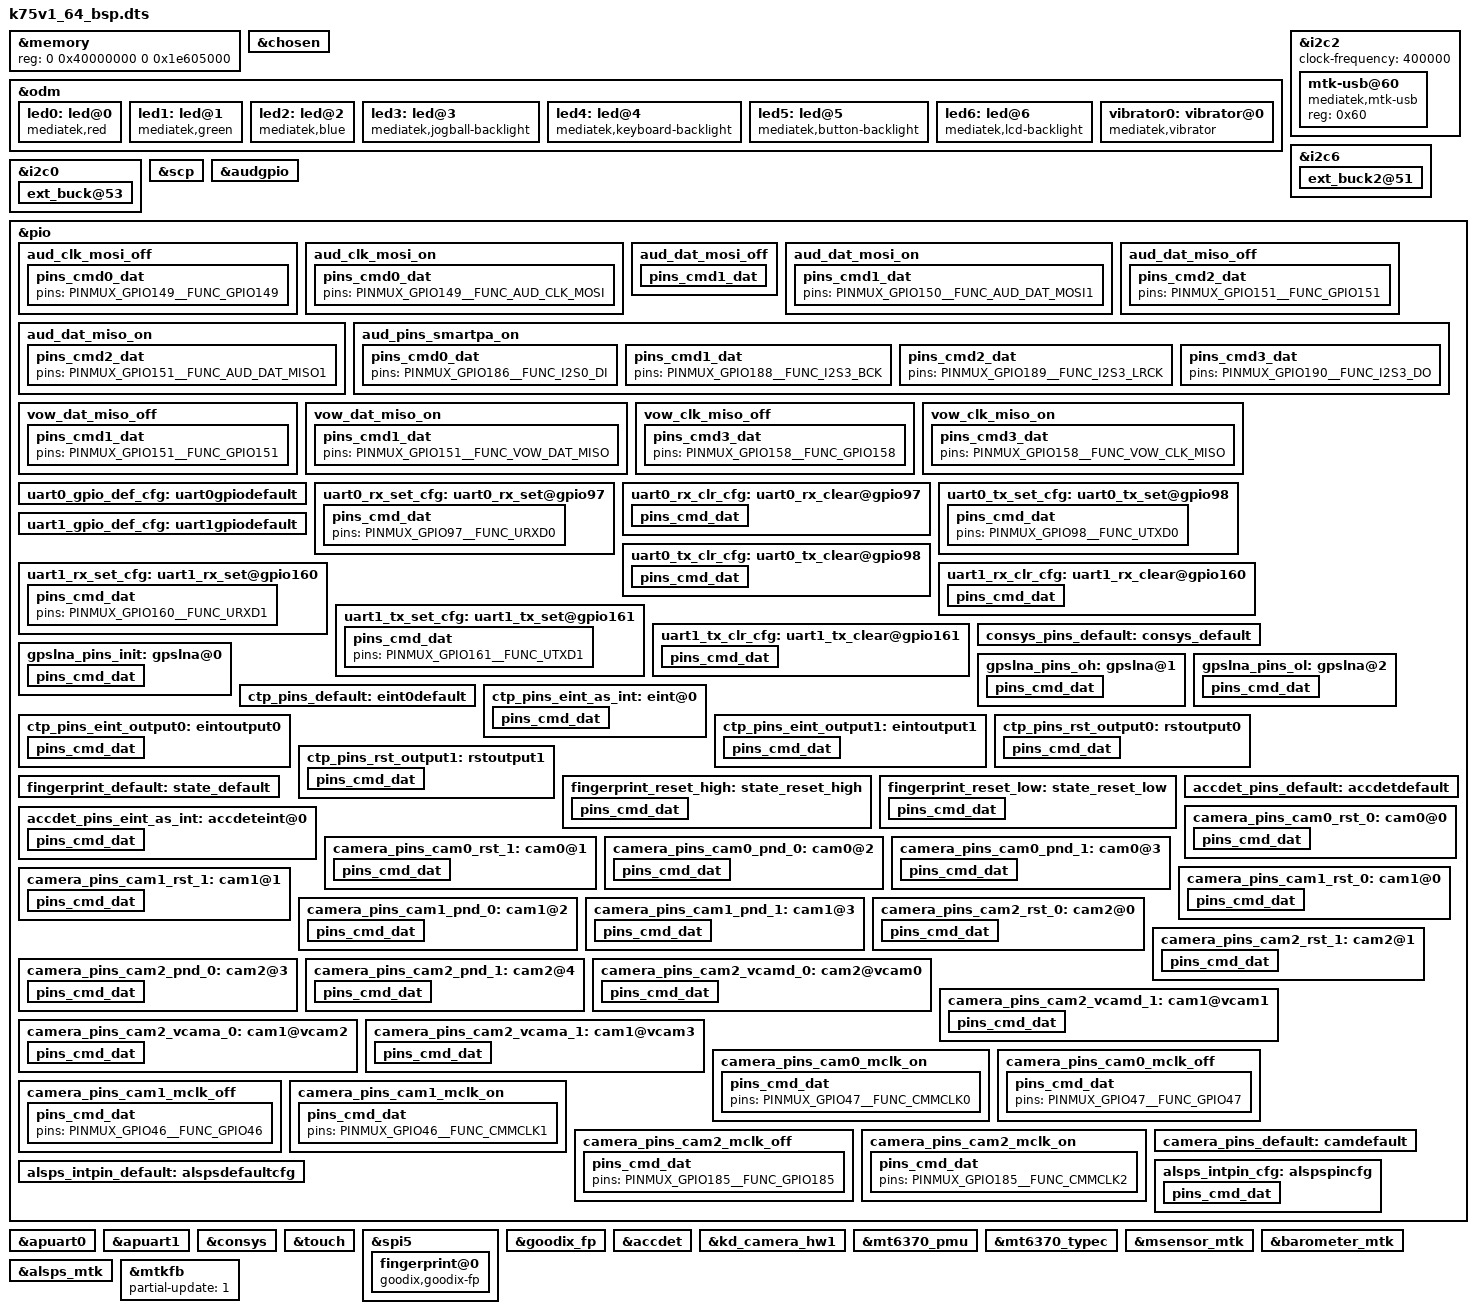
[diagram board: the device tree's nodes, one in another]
/dts-v1/;
/plugin/;
#include <dt-bindings/interrupt-controller/arm-gic.h>
#include <dt-bindings/interrupt-controller/irq.h>
#include <dt-bindings/pinctrl/mt6775-pinfunc.h>

&memory {
	device_type = "memory";
	reg = <0 0x40000000 0 0x1e605000>;
};

/* chosen */
&chosen {
	bootargs = "console=tty0 console=ttyMT0,921600n1 root=/dev/ram \
initrd=0x45000000,0x3000000 loglevel=8 \
androidboot.selinux=permissive androidboot.hardware=mt6775 \
initcall_debug=1";
	/* fpga may has no lk, we need to specify display info here */
	/* fb buffer is reserved using this dts by memory node above */

	atag,videolfb-fb_base_l = <0x5e605000>;
	atag,videolfb-fb_base_h = <0x0>;
	atag,videolfb-islcmfound = <1>;
	atag,videolfb-islcm_inited = <0>;
	atag,videolfb-fps= <6000>;
	atag,videolfb-vramSize= <0x017bb000>;
	/* atag,videolfb-lcmname= "nt35695B_fhd_dsi_cmd_truly_rt5081_lcm_drv"; */
	atag,videolfb-lcmname= "nt35695B_fhd_dsi_cmd_auo_rt5081_drv";

};

&odm {
	led0:led@0 {
		compatible = "mediatek,red";
		led_mode = <0>;
		data = <1>;
		pwm_config = <0 0 0 0 0>;
	};
	led1:led@1 {
		compatible = "mediatek,green";
		led_mode = <0>;
		data = <1>;
		pwm_config = <0 0 0 0 0>;
	};
	led2:led@2 {
		compatible = "mediatek,blue";
		led_mode = <0>;
		data = <1>;
		pwm_config = <0 0 0 0 0>;
	};
	led3:led@3 {
		compatible = "mediatek,jogball-backlight";
		led_mode = <0>;
		data = <1>;
		pwm_config = <0 0 0 0 0>;
	};
	led4:led@4 {
		compatible = "mediatek,keyboard-backlight";
		led_mode = <0>;
		data = <1>;
		pwm_config = <0 0 0 0 0>;
	};
	led5:led@5 {
		compatible = "mediatek,button-backlight";
		led_mode = <0>;
		data = <1>;
		pwm_config = <0 0 0 0 0>;
	};
	led6:led@6 {
		compatible = "mediatek,lcd-backlight";
		led_mode = <5>;
		data = <1>;
		pwm_config = <0 1 0 0 0>;
	};
	vibrator0:vibrator@0 {
		compatible = "mediatek,vibrator";
		vib_timer = <25>;
		vib_limit = <9>;
		vib_vol= <9>;
	};
};

&i2c2 {
	#address-cells = <1>;
	#size-cells = <0>;
	clock-frequency = <400000>;

	mtk-usb@60 {
		compatible = "mediatek,mtk-usb";
		reg = <0x60>;
		status = "okay";
	};
};

&i2c6 {
	ext_buck2@51 {
		regulator-name = "ext_buck_vpu";
		regulator-min-microvolt = <300000>;
		regulator-max-microvolt = <1300000>;
		vsel_pin = <0>;
	};
};

&i2c0 {
	ext_buck@53 {
		regulator-name = "ext_buck_cpul";
		regulator-min-microvolt = <300000>;
		regulator-max-microvolt = <1300000>;
		vsel_pin = <1>;
	};
};

&scp {
	core_1 = "enable";
	scp_sramSize = <0x00080000>;	 /* scp_A_sram_size */
};

/* AUDIO GPIO standardization */
&audgpio {
	pinctrl-names = "aud_clk_mosi_off",
			"aud_clk_mosi_on",
			"aud_dat_mosi_off",
			"aud_dat_mosi_on",
			"aud_dat_miso_off",
			"aud_dat_miso_on",
			"aud_smartpa_on",
			"vow_dat_miso_off",
			"vow_dat_miso_on",
			"vow_clk_miso_off",
			"vow_clk_miso_on";
	pinctrl-0 = <&aud_clk_mosi_off>;
	pinctrl-1 = <&aud_clk_mosi_on>;
	pinctrl-2 = <&aud_dat_mosi_off>;
	pinctrl-3 = <&aud_dat_mosi_on>;
	pinctrl-4 = <&aud_dat_miso_off>;
	pinctrl-5 = <&aud_dat_miso_on>;
	pinctrl-6 = <&aud_pins_smartpa_on>;
	pinctrl-7 = <&vow_dat_miso_off>;
	pinctrl-8 = <&vow_dat_miso_on>;
	pinctrl-9 = <&vow_clk_miso_off>;
	pinctrl-10 = <&vow_clk_miso_on>;
	status = "okay";
};

&pio {
	aud_clk_mosi_off: aud_clk_mosi_off {
		pins_cmd0_dat {
			pins = <PINMUX_GPIO149__FUNC_GPIO149>;
		};
	};

	aud_clk_mosi_on: aud_clk_mosi_on {
		pins_cmd0_dat {
			pins = <PINMUX_GPIO149__FUNC_AUD_CLK_MOSI>;
		};
	};

	aud_dat_mosi_off: aud_dat_mosi_off {
		pins_cmd1_dat {
			pins = <PINMUX_GPIO150__FUNC_GPIO150>;
			slew-rate = <0>;
			bias-pull-down = <MTK_PUPD_SET_R1R0_00>;
		};
	};

	aud_dat_mosi_on: aud_dat_mosi_on {
		pins_cmd1_dat {
			pins = <PINMUX_GPIO150__FUNC_AUD_DAT_MOSI1>;
		};
	};

	aud_dat_miso_off: aud_dat_miso_off {
		pins_cmd2_dat {
			pins = <PINMUX_GPIO151__FUNC_GPIO151>;
		};
	};

	aud_dat_miso_on: aud_dat_miso_on {
		pins_cmd2_dat {
			pins = <PINMUX_GPIO151__FUNC_AUD_DAT_MISO1>;
		};
	};

	aud_pins_smartpa_on: aud_pins_smartpa_on {
		pins_cmd0_dat {
			pins = <PINMUX_GPIO186__FUNC_I2S0_DI>;
		};
		pins_cmd1_dat {
			pins = <PINMUX_GPIO188__FUNC_I2S3_BCK>;
		};
		pins_cmd2_dat {
			pins = <PINMUX_GPIO189__FUNC_I2S3_LRCK>;
		};
		pins_cmd3_dat {
			pins = <PINMUX_GPIO190__FUNC_I2S3_DO>;
		};
	};

	vow_dat_miso_off: vow_dat_miso_off {
		pins_cmd1_dat {
			pins = <PINMUX_GPIO151__FUNC_GPIO151>;
		};
	};

	vow_dat_miso_on: vow_dat_miso_on {
		pins_cmd1_dat {
			pins = <PINMUX_GPIO151__FUNC_VOW_DAT_MISO>;
		};
	};

	vow_clk_miso_off: vow_clk_miso_off {
		pins_cmd3_dat {
			pins = <PINMUX_GPIO158__FUNC_GPIO158>;
		};
	};

	vow_clk_miso_on: vow_clk_miso_on {
		pins_cmd3_dat {
			pins = <PINMUX_GPIO158__FUNC_VOW_CLK_MISO>;
		};
	};
};
/* AUDIO end */

/* UART start*/
&apuart0 {
	pinctrl-names = "uart0_gpio_default",
			"uart0_rx_set",
			"uart0_rx_clear",
			"uart0_tx_set",
			"uart0_tx_clear";

	pinctrl-0 = <&uart0_gpio_def_cfg>;
	pinctrl-1 = <&uart0_rx_set_cfg>;
	pinctrl-2 = <&uart0_rx_clr_cfg>;
	pinctrl-3 = <&uart0_tx_set_cfg>;
	pinctrl-4 = <&uart0_tx_clr_cfg>;
	status = "okay";
};

&apuart1 {
	pinctrl-names = "uart1_gpio_default",
			"uart1_rx_set",
			"uart1_rx_clear",
			"uart1_tx_set",
			"uart1_tx_clear";

	pinctrl-0 = <&uart1_gpio_def_cfg>;
	pinctrl-1 = <&uart1_rx_set_cfg>;
	pinctrl-2 = <&uart1_rx_clr_cfg>;
	pinctrl-3 = <&uart1_tx_set_cfg>;
	pinctrl-4 = <&uart1_tx_clr_cfg>;
	status = "okay";
};

&pio {
	/* UART0: rx set, rx clear, tx clear, tx clear*/
	uart0_gpio_def_cfg:uart0gpiodefault {
	};
	uart0_rx_set_cfg:uart0_rx_set@gpio97 {
		pins_cmd_dat {
			pins = <PINMUX_GPIO97__FUNC_URXD0>;
		};
	};
	uart0_rx_clr_cfg:uart0_rx_clear@gpio97  {
		pins_cmd_dat {
			pins = <PINMUX_GPIO97__FUNC_GPIO97>;
			slew-rate = <1>;
			output-high;
		};
	};
	uart0_tx_set_cfg:uart0_tx_set@gpio98  {
		pins_cmd_dat {
			pins = <PINMUX_GPIO98__FUNC_UTXD0>;
		};
	};
	uart0_tx_clr_cfg:uart0_tx_clear@gpio98  {
		pins_cmd_dat {
			pins = <PINMUX_GPIO98__FUNC_GPIO98>;
			slew-rate = <1>;
			output-high;
		};
	};
	/* UART1: rx set, rx clear, tx clear, tx clear*/
	uart1_gpio_def_cfg:uart1gpiodefault {
	};
	uart1_rx_set_cfg:uart1_rx_set@gpio160 {
		pins_cmd_dat {
			pins = <PINMUX_GPIO160__FUNC_URXD1>;
		};
	};
	uart1_rx_clr_cfg:uart1_rx_clear@gpio160 {
		pins_cmd_dat {
			pins = <PINMUX_GPIO160__FUNC_GPIO160>;
			slew-rate = <1>;
			output-high;
		};
	};
	uart1_tx_set_cfg:uart1_tx_set@gpio161 {
		pins_cmd_dat {
			pins = <PINMUX_GPIO161__FUNC_UTXD1>;
		};
	};
	uart1_tx_clr_cfg:uart1_tx_clear@gpio161 {
		pins_cmd_dat {
			pins = <PINMUX_GPIO161__FUNC_GPIO161>;
			slew-rate = <1>;
			output-high;
		};
	};
};
/* UART end*/

/* CONSYS GPIO standardization */
&pio {
	consys_pins_default: consys_default {
	};
	gpslna_pins_init: gpslna@0 {
		pins_cmd_dat {
			pins = <PINMUX_GPIO183__FUNC_GPIO183>;
			slew-rate = <0>;
			bias-disable;
			output-low;
		};
	};
	gpslna_pins_oh: gpslna@1 {
		pins_cmd_dat {
			pins = <PINMUX_GPIO183__FUNC_GPIO183>;
			slew-rate = <1>;
			output-high;
		};
	};
	gpslna_pins_ol: gpslna@2 {
		pins_cmd_dat {
			pins = <PINMUX_GPIO183__FUNC_GPIO183>;
			slew-rate = <1>;
			output-low;
		};
	};
};
&consys {
	pinctrl-names = "default", "gps_lna_state_init", "gps_lna_state_oh", "gps_lna_state_ol";
	pinctrl-0 = <&consys_pins_default>;
	pinctrl-1 = <&gpslna_pins_init>;
	pinctrl-2 = <&gpslna_pins_oh>;
	pinctrl-3 = <&gpslna_pins_ol>;
	status = "okay";
};
/* CONSYS end */

/* TOUCH start */
&touch {
	tpd-resolution = <1080 1920>;
	use-tpd-button = <0>;
	tpd-key-num = <3>;
	tpd-key-local= <139 172 158 0>;
	tpd-key-dim-local = <90 883 100 40 230 883 100 40 370 883 100 40 0 0 0 0>;
	tpd-max-touch-num = <5>;
	tpd-filter-enable = <0>;
	tpd-filter-pixel-density = <146>;
	tpd-filter-custom-prameters = <0 0 0 0 0 0 0 0 0 0 0 0>;
	tpd-filter-custom-speed = <0 0 0>;
	pinctrl-names = "default", "state_eint_as_int", "state_eint_output0", "state_eint_output1",
		"state_rst_output0", "state_rst_output1";
	pinctrl-0 = <&ctp_pins_default>;
	pinctrl-1 = <&ctp_pins_eint_as_int>;
	pinctrl-2 = <&ctp_pins_eint_output0>;
	pinctrl-3 = <&ctp_pins_eint_output1>;
	pinctrl-4 = <&ctp_pins_rst_output0>;
	pinctrl-5 = <&ctp_pins_rst_output1>;
	status = "okay";
};
&pio {
	ctp_pins_default: eint0default {
	};
	ctp_pins_eint_as_int: eint@0 {
		pins_cmd_dat {
			pins = <PINMUX_GPIO2__FUNC_GPIO2>;
			slew-rate = <0>;
			bias-disable;
		};
	};
	ctp_pins_eint_output0: eintoutput0 {
		pins_cmd_dat {
			pins = <PINMUX_GPIO2__FUNC_GPIO2>;
			slew-rate = <1>;
			output-low;
		};
	};
	ctp_pins_eint_output1: eintoutput1 {
		pins_cmd_dat {
			pins = <PINMUX_GPIO2__FUNC_GPIO2>;
			slew-rate = <1>;
			output-high;
		};
	};
	ctp_pins_rst_output0: rstoutput0 {
		pins_cmd_dat {
			pins = <PINMUX_GPIO3__FUNC_GPIO3>;
			slew-rate = <1>;
			output-low;
		};
	};
	ctp_pins_rst_output1: rstoutput1 {
		pins_cmd_dat {
			pins = <PINMUX_GPIO3__FUNC_GPIO3>;
			slew-rate = <1>;
			output-high;
		};
	};
};
/* TOUCH end */

/* FINGERPRINT start */
&spi5 {
	#address-cells = <1>;
	#size-cells = <0>;

	fingerprint@0 {
		compatible = "goodix,goodix-fp";
		reg = <0>;
		spi-max-frequency = <8000000>;
		netlink-event = <30>;
		mt6306-rst-support = <0>;
		mt6306-rst-gpionum = <6>;
		status = "okay";
	};
};

&goodix_fp {
	pinctrl-names = "default", "reset_high", "reset_low";
	pinctrl-0 = <&fingerprint_default>;
	pinctrl-1 = <&fingerprint_reset_high>;
	pinctrl-2 = <&fingerprint_reset_low>;
	status = "okay";
};

&pio {
	fingerprint_default: state_default {

	};

	fingerprint_reset_high: state_reset_high {
		pins_cmd_dat {
			pins = <PINMUX_GPIO136__FUNC_GPIO136>;
			slew-rate = <1>;
			output-high;
		};
	};

	fingerprint_reset_low: state_reset_low {
		pins_cmd_dat {
			pins = <PINMUX_GPIO136__FUNC_GPIO136>;
			slew-rate = <1>;
			output-low;
		};
	};
};
/* FINGERPRINT end */

/* accdet start */
&accdet {
/* accdet micbias voltage: 0x07,2.7v;0x05,2.5v;0x02,1.9v */
	accdet-mic-vol = <7>;
	headset-mode-setting = <0x500 0x500 1 0x1f0 0x800 0x800 0x20>;
	accdet-plugout-debounce = <1>;
/* 1:ACC mode, 2:low cost without in bias, 6:low cost with in bias */
	accdet-mic-mode = <2>;
/* eint_level_trigger:8,LEVEL_LOW(default);4,LEVEL_HIGH;others,LEVEL_LOW */
	headset-eint-level-pol = <8>;
/*0--MD_MAX--UP_MAX--DW_MAX*/
	headset-three-key-threshold = <0 80 220 400>;
	headset-three-key-threshold-CDD = <0 121 192 600>;
/*0--MD_MAX--VOICE_MAX--UP_MAX--DW_MAX*/
	headset-four-key-threshold = <0 58 121 192 400>;
/* ACCDET GPIO standardization ACC mode no use */
	pinctrl-names = "default", "state_eint_as_int";
	pinctrl-0 = <&accdet_pins_default>;
	pinctrl-1 = <&accdet_pins_eint_as_int>;
	status = "okay";
};
&pio {
	accdet_pins_default: accdetdefault {
	};
	accdet_pins_eint_as_int: accdeteint@0 {
		pins_cmd_dat {
			pins = <PINMUX_GPIO9__FUNC_GPIO9>;
			slew-rate = <0>;
			bias-disable;
		};
	};
};
/* accdet end */

/* CAMERA GPIO standardization */
&pio {
	camera_pins_cam0_rst_0: cam0@0 {
		pins_cmd_dat {
			pins = <PINMUX_GPIO43__FUNC_GPIO43>;
			slew-rate = <1>;
			output-low;
		};
	};
	camera_pins_cam0_rst_1: cam0@1 {
		pins_cmd_dat {
			pins = <PINMUX_GPIO43__FUNC_GPIO43>;
			slew-rate = <1>;
			output-high;
		};
	};
	camera_pins_cam0_pnd_0: cam0@2 {
		pins_cmd_dat {
			pins = <PINMUX_GPIO42__FUNC_GPIO42>;
			slew-rate = <1>;
			output-low;
		};
	};
	camera_pins_cam0_pnd_1: cam0@3 {
		pins_cmd_dat {
			pins = <PINMUX_GPIO42__FUNC_GPIO42>;
			slew-rate = <1>;
			output-high;
		};
	};
	camera_pins_cam1_rst_0: cam1@0 {
		pins_cmd_dat {
			pins = <PINMUX_GPIO45__FUNC_GPIO45>;
			slew-rate = <1>; /*direction 0:in, 1:out*/
			output-low;/*direction out used only. output_low or high*/
		};
	};
	camera_pins_cam1_rst_1: cam1@1 {
		pins_cmd_dat {
			pins = <PINMUX_GPIO45__FUNC_GPIO45>;
			slew-rate = <1>;
			output-high;
		};
	};
	camera_pins_cam1_pnd_0: cam1@2 {
		pins_cmd_dat {
			pins = <PINMUX_GPIO44__FUNC_GPIO44>;
			slew-rate = <1>;
			output-low;
		};
	};
	camera_pins_cam1_pnd_1: cam1@3 {
		pins_cmd_dat {
			pins = <PINMUX_GPIO44__FUNC_GPIO44>;
			slew-rate = <1>;
			output-high;
		};
	};
	camera_pins_cam2_rst_0: cam2@0 {
		pins_cmd_dat {
			pins = <PINMUX_GPIO184__FUNC_GPIO184>;
			slew-rate = <1>;
			output-low;
		};
	};
	camera_pins_cam2_rst_1: cam2@1 {
		pins_cmd_dat {
			pins = <PINMUX_GPIO184__FUNC_GPIO184>;
			slew-rate = <1>;
			output-high;
		};
	};
	camera_pins_cam2_pnd_0: cam2@3 {
		pins_cmd_dat {
			pins = <PINMUX_GPIO182__FUNC_GPIO182>;
			slew-rate = <1>;
			output-low;
		};
	};
	camera_pins_cam2_pnd_1: cam2@4 {
		pins_cmd_dat {
			pins = <PINMUX_GPIO182__FUNC_GPIO182>;
			slew-rate = <1>;
			output-high;
		};
	};
	camera_pins_cam2_vcamd_0: cam2@vcam0 {
		pins_cmd_dat {
			pins = <PINMUX_GPIO120__FUNC_GPIO120>;
			slew-rate = <1>;
			output-low;
		};
	};
	camera_pins_cam2_vcamd_1: cam1@vcam1 {
		pins_cmd_dat {
			pins = <PINMUX_GPIO120__FUNC_GPIO120>;
			slew-rate = <1>;
			output-high;
		};
	};
	camera_pins_cam2_vcama_0: cam1@vcam2 {
		pins_cmd_dat {
			pins = <PINMUX_GPIO120__FUNC_GPIO120>;
			slew-rate = <1>;
			output-low;
		};
	};
	camera_pins_cam2_vcama_1: cam1@vcam3 {
		pins_cmd_dat {
			pins = <PINMUX_GPIO120__FUNC_GPIO120>;
			slew-rate = <1>;
			output-high;
		};
	};
	camera_pins_cam0_mclk_on: camera_pins_cam0_mclk_on {
		pins_cmd_dat {
			pins = <PINMUX_GPIO47__FUNC_CMMCLK0>;
		};
	};
	camera_pins_cam0_mclk_off: camera_pins_cam0_mclk_off {
		pins_cmd_dat {
			pins = <PINMUX_GPIO47__FUNC_GPIO47>;
		};
	};
	camera_pins_cam1_mclk_off: camera_pins_cam1_mclk_off {
		pins_cmd_dat {
			pins = <PINMUX_GPIO46__FUNC_GPIO46>;
		};
	};
	camera_pins_cam1_mclk_on: camera_pins_cam1_mclk_on {
		pins_cmd_dat {
			pins = <PINMUX_GPIO46__FUNC_CMMCLK1>;
		};
	};
	camera_pins_cam2_mclk_off: camera_pins_cam2_mclk_off {
		pins_cmd_dat {
			pins = <PINMUX_GPIO185__FUNC_GPIO185>;
		};
	};
	camera_pins_cam2_mclk_on: camera_pins_cam2_mclk_on {
		pins_cmd_dat {
			pins = <PINMUX_GPIO185__FUNC_CMMCLK2>;
		};
	};
	camera_pins_default: camdefault {
	};
};
&kd_camera_hw1 {
	pinctrl-names = "default",
			"cam0_rst0", "cam0_rst1",
			"cam0_pnd0", "cam0_pnd1",
			"cam1_rst0", "cam1_rst1",
			"cam1_pnd0", "cam1_pnd1",
			"cam2_rst0", "cam2_rst1",
			"cam2_pnd0", "cam2_pnd1",
			"cam_ldo_main2_vcamd_0", "cam_ldo_main2_vcamd_1",
			"cam_ldo_main2_vcama_0", "cam_ldo_main2_vcama_1",
			"cam0_mclk_off", "cam0_mclk_on",
			"cam1_mclk_off", "cam1_mclk_on",
			"cam2_mclk_off", "cam2_mclk_on";
	pinctrl-0 = <&camera_pins_default>;
	pinctrl-1 = <&camera_pins_cam0_rst_0>;
	pinctrl-2 = <&camera_pins_cam0_rst_1>;
	pinctrl-3 = <&camera_pins_cam0_pnd_0>;
	pinctrl-4 = <&camera_pins_cam0_pnd_1>;
	pinctrl-5 = <&camera_pins_cam1_rst_0>;
	pinctrl-6 = <&camera_pins_cam1_rst_1>;
	pinctrl-7 = <&camera_pins_cam1_pnd_0>;
	pinctrl-8 = <&camera_pins_cam1_pnd_1>;
	pinctrl-9 = <&camera_pins_cam2_rst_0>;
	pinctrl-10 = <&camera_pins_cam2_rst_1>;
	pinctrl-11 = <&camera_pins_cam2_pnd_0>;
	pinctrl-12 = <&camera_pins_cam2_pnd_1>;
	pinctrl-13 = <&camera_pins_cam2_vcamd_0>;
	pinctrl-14 = <&camera_pins_cam2_vcamd_1>;
	pinctrl-15 = <&camera_pins_cam2_vcama_0>;
	pinctrl-16 = <&camera_pins_cam2_vcama_1>;
	pinctrl-17 = <&camera_pins_cam0_mclk_off>;
	pinctrl-18 = <&camera_pins_cam0_mclk_on>;
	pinctrl-19 = <&camera_pins_cam1_mclk_off>;
	pinctrl-20 = <&camera_pins_cam1_mclk_on>;
	pinctrl-21 = <&camera_pins_cam2_mclk_off>;
	pinctrl-22 = <&camera_pins_cam2_mclk_on>;

	status = "okay";
};

&mt6370_pmu {
	mt6370,intr_gpio_num = <12>; /* direct defined GPIO num */
	mt6370,intr_gpio = <&pio 12 0x0>;
};

&mt6370_typec {
	mt6370pd,intr_gpio_num = <15>; /* direct defined GPIO num */
	mt6370pd,intr_gpio = <&pio 15 0x0>;
};

/*  sensor start*/
&msensor_mtk {
		i2c_num = <1>;
		/* i2c_addr			= <0x0C 0 0 0>; */
		direction			= <5>;
		power_id = <0xffff>;
		power_vol = <0>;
		/* is_batch_supported = <0>; */
};

&barometer_mtk {
		i2c_num = <1>;
		/* i2c_addr = <0x77 0 0 0>; */
		direction = <0>;
		power_id = <0xffff>;
		power_vol = <0>;
		firlen = <32>;
		is_batch_supported = <0>;
};
/* sensor gpio standization */
&pio {
	alsps_intpin_cfg: alspspincfg {

		pins_cmd_dat {
			pins = <PINMUX_GPIO6__FUNC_GPIO6>;
			slew-rate = <0>;
			bias-pull-up = <00>;
		};
	};

	alsps_intpin_default: alspsdefaultcfg {

	};
};

&alsps_mtk {
	pinctrl-names = "pin_default", "pin_cfg";
	pinctrl-0 = <&alsps_intpin_default>;
	pinctrl-1 = <&alsps_intpin_cfg>;
	status = "okay";
	/* customization */
	i2c_num = <1>;
	i2c_addr = <0x51 0 0 0>;
	polling_mode_ps = <0>;
	polling_mode_als = <1>;
	power_id = <0xffff>;
	power_vol = <0>;
	als_level = <0 328 861 1377 3125 7721 7767 12621 23062 28430 33274 47116 57694 57694 65535>;
	als_value = <0 133 304 502 1004 2005 3058 5005 8008 10010 12000 16000 20000 20000 20000 20000>;
	ps_threshold_high = <26>;
	ps_threshold_low = <21>;
	is_batch_supported_ps = <0>;
	is_batch_supported_als = <0>;
};
/* sensor end */

&mtkfb {
	partial-update = <1>;
	status = "okay";
};

#include <k75v1_64_bsp/cust.dtsi>
/*End of this file, DO NOT ADD ANYTHING HERE*/
